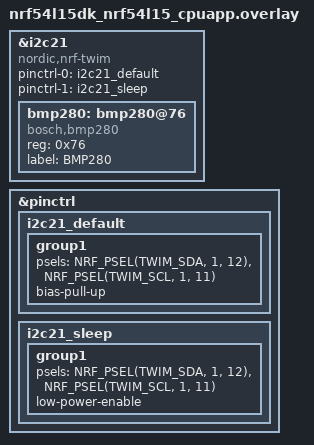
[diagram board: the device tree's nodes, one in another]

&i2c21 {
	compatible = "nordic,nrf-twim";
	status = "okay";
	pinctrl-0 = <&i2c21_default>;
	pinctrl-1 = <&i2c21_sleep>;
	pinctrl-names = "default", "sleep";

	 bmp280: bmp280@76 {
        compatible = "bosch,bmp280";
        reg = <0x76>;
        label = "BMP280";
    };
};

&pinctrl {
	i2c21_default: i2c21_default {
		group1 {
			psels = <NRF_PSEL(TWIM_SDA, 1, 12)>,
				<NRF_PSEL(TWIM_SCL, 1, 11)>;
			bias-pull-up;
		};
	};

	i2c21_sleep: i2c21_sleep {
		group1 {
			psels = <NRF_PSEL(TWIM_SDA, 1, 12)>,
				<NRF_PSEL(TWIM_SCL, 1, 11)>;
			low-power-enable;
		};
	};
};
